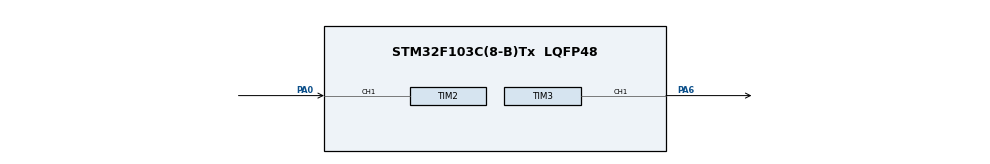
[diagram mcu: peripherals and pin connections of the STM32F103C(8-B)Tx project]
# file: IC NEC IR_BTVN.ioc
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Mcu.Family=STM32F1
Mcu.Name=STM32F103C(8-B)Tx
Mcu.Package=LQFP48
NVIC.PriorityGroup=NVIC_PRIORITYGROUP_4
NVIC.TIM2_IRQn=true\:0\:0\:false\:false\:true\:true\:true\:true
PA0-WKUP.Signal=S_TIM2_CH1_ETR
PA13.Mode=Serial_Wire
PA13.Signal=SYS_JTMS-SWDIO
PA14.Mode=Serial_Wire
PA14.Signal=SYS_JTCK-SWCLK
PA6.Signal=S_TIM3_CH1
ProjectManager.HeapSize=0x200
ProjectManager.StackSize=0x400
ProjectManager.TargetToolchain=MDK-ARM V5
RCC.APB1Freq_Value=8000000
RCC.APB2Freq_Value=8000000
SH.S_TIM2_CH1_ETR.0=TIM2_CH1,Input_Capture1_from_TI1
SH.S_TIM3_CH1.0=TIM3_CH1,PWM Generation1 CH1
TIM2.Channel-Input_Capture1_from_TI1=TIM_CHANNEL_1
TIM2.ICPolarity_CH1=TIM_INPUTCHANNELPOLARITY_FALLING
TIM2.Prescaler=800-1
TIM3.Channel-PWM\ Generation1\ CH1=TIM_CHANNEL_1
TIM3.Period=2000-1
TIM3.Prescaler=800-1
VP_TIM2_VS_ClockSourceINT.Mode=Internal
board=custom

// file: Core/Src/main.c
/* USER CODE BEGIN Header */
/**
  ******************************************************************************
  * @file           : main.c
  * @brief          : Main program body
  ******************************************************************************
  * @attention
  *
  * Copyright (c) 2023 STMicroelectronics.
  * All rights reserved.
  *
  * This software is licensed under terms that can be found in the LICENSE file
  * in the root directory of this software component.
  * If no LICENSE file comes with this software, it is provided AS-IS.
  *
  ******************************************************************************
  */
/* USER CODE END Header */
#include "main.h"

TIM_HandleTypeDef htim2;
TIM_HandleTypeDef htim3;

/* USER CODE BEGIN PV */
#define START_TIME_MAX 140
#define START_TIME_MIN 120
#define COMMAND_0  15
/* define Button for remote*/
#define BUTTON_0 0x98
#define BUTTON_1 0xA2
#define BUTTON_2 0x62
#define BUTTON_3 0xE2
#define BUTTON_4 0x22
#define BUTTON_5 0x02

uint16_t Time1 = 0;
uint16_t Time2 = 0;
uint16_t Period = 0;

uint8_t counter_hex = 0;
uint8_t command = 0;
uint32_t hex_ir = 0;

void ControlPWM(uint16_t Duty){
	__HAL_TIM_SetCompare(&htim3,TIM_CHANNEL_1,Duty);
}

void ControlOutput(void){
	static uint16_t LedDuty;
	switch(command){
				case BUTTON_0:	//button 0
					LedDuty=0;
					break;
				case BUTTON_1:	//button 1
					LedDuty=400;
					break;
				case BUTTON_2:	//button 2
					LedDuty=800;
					break;
				case BUTTON_3:	//button 3
					LedDuty=1200;
					break;
				case BUTTON_4:	//button 4
					LedDuty=1600;
					break;
				case BUTTON_5:	//button 5
					LedDuty=2000;
					break;
			}
	ControlPWM(LedDuty);
}

void HAL_TIM_IC_CaptureCallback(TIM_HandleTypeDef *htim)
{
		Time2 = HAL_TIM_ReadCapturedValue(htim, TIM_CHANNEL_1);
		Period = Time2 - Time1;
		Time1 = Time2;

		//kiem tra xung
		if(Period < START_TIME_MAX && Period > START_TIME_MIN)
		{
			hex_ir = 0;
			counter_hex = 0;
		}
		else if(Period > COMMAND_0) //bit 1
		{
			hex_ir |=(1<<(31-counter_hex));
			counter_hex++;
		}
		else if(Period < COMMAND_0) //bit 0
		{
			counter_hex++;
		}

		if(counter_hex == 32) //ghi 32 lan
		{
			command = hex_ir>>8;
			ControlOutput();
		}

}
/* USER CODE END PV */

void SystemClock_Config(void);
static void MX_GPIO_Init(void);
static void MX_TIM2_Init(void);
static void MX_TIM3_Init(void);

int main(void)
{

  /* MCU Configuration--------------------------------------------------------*/

  /* Reset of all peripherals, Initializes the Flash interface and the Systick. */
  HAL_Init();

  /* Configure the system clock */
  SystemClock_Config();

  /* Initialize all configured peripherals */
  MX_GPIO_Init();
  MX_TIM2_Init();
  MX_TIM3_Init();
  /* USER CODE BEGIN 2 */
	HAL_TIM_IC_Start_IT(&htim2, TIM_CHANNEL_1);
	HAL_TIM_PWM_Start(&htim3,TIM_CHANNEL_1);
  /* USER CODE END 2 */

  /* Infinite loop */
  while (1)
  {

  }
}

void SystemClock_Config(void)
{
  RCC_OscInitTypeDef RCC_OscInitStruct = {0};
  RCC_ClkInitTypeDef RCC_ClkInitStruct = {0};

  /** Initializes the RCC Oscillators according to the specified parameters
  * in the RCC_OscInitTypeDef structure.
  */
  RCC_OscInitStruct.OscillatorType = RCC_OSCILLATORTYPE_HSI;
  RCC_OscInitStruct.HSIState = RCC_HSI_ON;
  RCC_OscInitStruct.HSICalibrationValue = RCC_HSICALIBRATION_DEFAULT;
  RCC_OscInitStruct.PLL.PLLState = RCC_PLL_NONE;
  if (HAL_RCC_OscConfig(&RCC_OscInitStruct) != HAL_OK)
  {
    Error_Handler();
  }

  /** Initializes the CPU, AHB and APB buses clocks
  */
  RCC_ClkInitStruct.ClockType = RCC_CLOCKTYPE_HCLK|RCC_CLOCKTYPE_SYSCLK
                              |RCC_CLOCKTYPE_PCLK1|RCC_CLOCKTYPE_PCLK2;
  RCC_ClkInitStruct.SYSCLKSource = RCC_SYSCLKSOURCE_HSI;
  RCC_ClkInitStruct.AHBCLKDivider = RCC_SYSCLK_DIV1;
  RCC_ClkInitStruct.APB1CLKDivider = RCC_HCLK_DIV1;
  RCC_ClkInitStruct.APB2CLKDivider = RCC_HCLK_DIV1;

  if (HAL_RCC_ClockConfig(&RCC_ClkInitStruct, FLASH_LATENCY_0) != HAL_OK)
  {
    Error_Handler();
  }
}

static void MX_TIM2_Init(void)
{

  TIM_ClockConfigTypeDef sClockSourceConfig = {0};
  TIM_MasterConfigTypeDef sMasterConfig = {0};
  TIM_IC_InitTypeDef sConfigIC = {0};

  htim2.Instance = TIM2;
  htim2.Init.Prescaler = 800-1;
  htim2.Init.CounterMode = TIM_COUNTERMODE_UP;
  htim2.Init.Period = 65535;
  htim2.Init.ClockDivision = TIM_CLOCKDIVISION_DIV1;
  htim2.Init.AutoReloadPreload = TIM_AUTORELOAD_PRELOAD_DISABLE;
  if (HAL_TIM_Base_Init(&htim2) != HAL_OK)
  {
    Error_Handler();
  }
  sClockSourceConfig.ClockSource = TIM_CLOCKSOURCE_INTERNAL;
  if (HAL_TIM_ConfigClockSource(&htim2, &sClockSourceConfig) != HAL_OK)
  {
    Error_Handler();
  }
  if (HAL_TIM_IC_Init(&htim2) != HAL_OK)
  {
    Error_Handler();
  }
  sMasterConfig.MasterOutputTrigger = TIM_TRGO_RESET;
  sMasterConfig.MasterSlaveMode = TIM_MASTERSLAVEMODE_DISABLE;
  if (HAL_TIMEx_MasterConfigSynchronization(&htim2, &sMasterConfig) != HAL_OK)
  {
    Error_Handler();
  }
  sConfigIC.ICPolarity = TIM_INPUTCHANNELPOLARITY_FALLING;
  sConfigIC.ICSelection = TIM_ICSELECTION_DIRECTTI;
  sConfigIC.ICPrescaler = TIM_ICPSC_DIV1;
  sConfigIC.ICFilter = 0;
  if (HAL_TIM_IC_ConfigChannel(&htim2, &sConfigIC, TIM_CHANNEL_1) != HAL_OK)
  {
    Error_Handler();
  }

}

static void MX_TIM3_Init(void)
{

  TIM_MasterConfigTypeDef sMasterConfig = {0};
  TIM_OC_InitTypeDef sConfigOC = {0};

  htim3.Instance = TIM3;
  htim3.Init.Prescaler = 800-1;
  htim3.Init.CounterMode = TIM_COUNTERMODE_UP;
  htim3.Init.Period = 2000-1;
  htim3.Init.ClockDivision = TIM_CLOCKDIVISION_DIV1;
  htim3.Init.AutoReloadPreload = TIM_AUTORELOAD_PRELOAD_DISABLE;
  if (HAL_TIM_PWM_Init(&htim3) != HAL_OK)
  {
    Error_Handler();
  }
  sMasterConfig.MasterOutputTrigger = TIM_TRGO_RESET;
  sMasterConfig.MasterSlaveMode = TIM_MASTERSLAVEMODE_DISABLE;
  if (HAL_TIMEx_MasterConfigSynchronization(&htim3, &sMasterConfig) != HAL_OK)
  {
    Error_Handler();
  }
  sConfigOC.OCMode = TIM_OCMODE_PWM1;
  sConfigOC.Pulse = 0;
  sConfigOC.OCPolarity = TIM_OCPOLARITY_HIGH;
  sConfigOC.OCFastMode = TIM_OCFAST_DISABLE;
  if (HAL_TIM_PWM_ConfigChannel(&htim3, &sConfigOC, TIM_CHANNEL_1) != HAL_OK)
  {
    Error_Handler();
  }
  HAL_TIM_MspPostInit(&htim3);

}

static void MX_GPIO_Init(void)
{

  /* GPIO Ports Clock Enable */
  __HAL_RCC_GPIOA_CLK_ENABLE();

}

void Error_Handler(void)
{
  __disable_irq();
  while (1)
  {
  }
}
